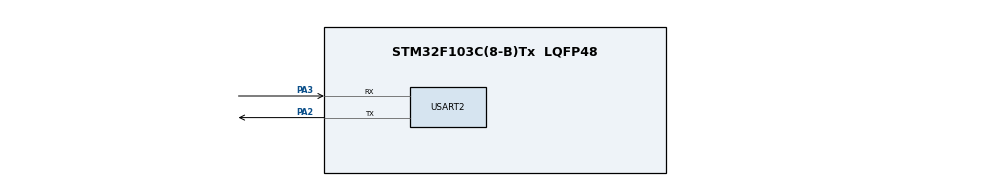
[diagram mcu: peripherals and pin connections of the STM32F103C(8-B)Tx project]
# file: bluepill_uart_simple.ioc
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Mcu.Family=STM32F1
Mcu.Name=STM32F103C(8-B)Tx
Mcu.Package=LQFP48
NVIC.PriorityGroup=NVIC_PRIORITYGROUP_4
PA13.Mode=Serial_Wire
PA13.Signal=SYS_JTMS-SWDIO
PA14.Mode=Serial_Wire
PA14.Signal=SYS_JTCK-SWCLK
PA2.Mode=Asynchronous
PA2.Signal=USART2_TX
PA3.Mode=Asynchronous
PA3.Signal=USART2_RX
ProjectManager.HeapSize=0x200
ProjectManager.StackSize=0x400
ProjectManager.TargetToolchain=Makefile
RCC.APB1Freq_Value=8000000
RCC.APB2Freq_Value=8000000
USART2.VirtualMode=VM_ASYNC
board=custom

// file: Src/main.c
/* USER CODE BEGIN Header */
/**
  ******************************************************************************
  * @file           : main.c
  * @brief          : Main program body
  ******************************************************************************
  * @attention
  *
  * <h2><center>&copy; Copyright (c) 2019 STMicroelectronics.
  * All rights reserved.</center></h2>
  *
  * This software component is licensed by ST under BSD 3-Clause license,
  * the "License"; You may not use this file except in compliance with the
  * License. You may obtain a copy of the License at:
  *                        opensource.org/licenses/BSD-3-Clause
  *
  ******************************************************************************
  */
/* USER CODE END Header */

#include "main.h"

UART_HandleTypeDef huart2;

/* USER CODE BEGIN PV */
uint8_t welcome[] = {'H','e','l','l','o'};
/* USER CODE END PV */

void SystemClock_Config(void);
static void MX_GPIO_Init(void);
static void MX_USART2_UART_Init(void);
/* USER CODE BEGIN PFP */
void write(uint8_t* data, uint32_t length);
int read(void);
/* USER CODE END PFP */

/* USER CODE BEGIN 0 */
int read(void) {
  uint8_t readByte;
  int retval = HAL_UART_Receive(&huart2, &readByte, 1, 1000);
  if(retval == HAL_ERROR)
  {
    return -1;
  }
  else
  {
    return (int) readByte;
  }

}

void write(uint8_t* data, uint32_t length)
{
  HAL_UART_Transmit(&huart2, data, length, 1000);
}
/* USER CODE END 0 */

int main(void)
{

  /* MCU Configuration--------------------------------------------------------*/

  /* Reset of all peripherals, Initializes the Flash interface and the Systick. */
  HAL_Init();

  /* Configure the system clock */
  SystemClock_Config();

  /* Initialize all configured peripherals */
  MX_GPIO_Init();
  MX_USART2_UART_Init();
  /* USER CODE BEGIN 2 */
    /* OFF_PIN needs to be high on hoverboard to get out of low power */
  #ifdef AT32F403Rx_HD
  HAL_GPIO_WritePin(OFF_GPIO_Port, OFF_Pin, 1);
  #endif
  write(welcome,5);
  /* USER CODE END 2 */

  /* Infinite loop */
  /* USER CODE BEGIN WHILE */
  while (1)
  {
    int readByte = read();
    welcome[0] = readByte;
    write(welcome,1);
    /* USER CODE END WHILE */

  }
}

void SystemClock_Config(void)
{
  RCC_OscInitTypeDef RCC_OscInitStruct = {0};
  RCC_ClkInitTypeDef RCC_ClkInitStruct = {0};

  /** Initializes the CPU, AHB and APB busses clocks
  */
  RCC_OscInitStruct.OscillatorType = RCC_OSCILLATORTYPE_HSI;
  RCC_OscInitStruct.HSIState = RCC_HSI_ON;
  RCC_OscInitStruct.HSICalibrationValue = RCC_HSICALIBRATION_DEFAULT;
  RCC_OscInitStruct.PLL.PLLState = RCC_PLL_NONE;
  if (HAL_RCC_OscConfig(&RCC_OscInitStruct) != HAL_OK)
  {
    Error_Handler();
  }
  /** Initializes the CPU, AHB and APB busses clocks
  */
  RCC_ClkInitStruct.ClockType = RCC_CLOCKTYPE_HCLK|RCC_CLOCKTYPE_SYSCLK
                              |RCC_CLOCKTYPE_PCLK1|RCC_CLOCKTYPE_PCLK2;
  RCC_ClkInitStruct.SYSCLKSource = RCC_SYSCLKSOURCE_HSI;
  RCC_ClkInitStruct.AHBCLKDivider = RCC_SYSCLK_DIV1;
  RCC_ClkInitStruct.APB1CLKDivider = RCC_HCLK_DIV1;
  RCC_ClkInitStruct.APB2CLKDivider = RCC_HCLK_DIV1;

  if (HAL_RCC_ClockConfig(&RCC_ClkInitStruct, FLASH_LATENCY_0) != HAL_OK)
  {
    Error_Handler();
  }
}

static void MX_USART2_UART_Init(void)
{

  huart2.Instance = USART2;
  huart2.Init.BaudRate = 115200;
  huart2.Init.WordLength = UART_WORDLENGTH_8B;
  huart2.Init.StopBits = UART_STOPBITS_1;
  huart2.Init.Parity = UART_PARITY_NONE;
  huart2.Init.Mode = UART_MODE_TX_RX;
  huart2.Init.HwFlowCtl = UART_HWCONTROL_NONE;
  huart2.Init.OverSampling = UART_OVERSAMPLING_16;
  if (HAL_UART_Init(&huart2) != HAL_OK)
  {
    Error_Handler();
  }

}

static void MX_GPIO_Init(void)
{
  /* GPIO Ports Clock Enable */
  __HAL_RCC_GPIOA_CLK_ENABLE();

#ifdef AT32F403Rx_HD
  GPIO_InitTypeDef GPIO_InitStruct = {0};

  /*Configure GPIO pin : OFF_PIN */
  GPIO_InitStruct.Pin = OFF_Pin;
  GPIO_InitStruct.Mode  = GPIO_MODE_OUTPUT_PP;
  GPIO_InitStruct.Pull  = GPIO_NOPULL;
  GPIO_InitStruct.Speed = GPIO_SPEED_FREQ_LOW;
  HAL_GPIO_Init(OFF_GPIO_Port, &GPIO_InitStruct);
#endif
}

void Error_Handler(void)
{
}

/************************ (C) COPYRIGHT STMicroelectronics *****END OF FILE****/
